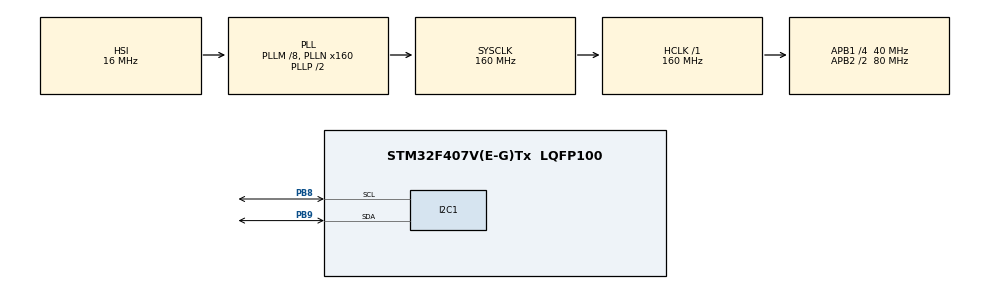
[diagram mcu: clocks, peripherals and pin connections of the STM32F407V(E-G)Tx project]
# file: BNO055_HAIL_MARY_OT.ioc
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Dma.I2C1_RX.1.Direction=DMA_PERIPH_TO_MEMORY
Dma.I2C1_RX.1.FIFOMode=DMA_FIFOMODE_DISABLE
Dma.I2C1_RX.1.Instance=DMA1_Stream0
Dma.I2C1_RX.1.MemDataAlignment=DMA_MDATAALIGN_BYTE
Dma.I2C1_RX.1.MemInc=DMA_MINC_ENABLE
Dma.I2C1_RX.1.Mode=DMA_NORMAL
Dma.I2C1_RX.1.PeriphDataAlignment=DMA_PDATAALIGN_BYTE
Dma.I2C1_RX.1.PeriphInc=DMA_PINC_DISABLE
Dma.I2C1_RX.1.Priority=DMA_PRIORITY_LOW
Dma.I2C1_TX.0.Direction=DMA_MEMORY_TO_PERIPH
Dma.I2C1_TX.0.FIFOMode=DMA_FIFOMODE_DISABLE
Dma.I2C1_TX.0.Instance=DMA1_Stream6
Dma.I2C1_TX.0.MemDataAlignment=DMA_MDATAALIGN_BYTE
Dma.I2C1_TX.0.MemInc=DMA_MINC_ENABLE
Dma.I2C1_TX.0.Mode=DMA_NORMAL
Dma.I2C1_TX.0.PeriphDataAlignment=DMA_PDATAALIGN_BYTE
Dma.I2C1_TX.0.PeriphInc=DMA_PINC_DISABLE
Dma.I2C1_TX.0.Priority=DMA_PRIORITY_LOW
Dma.Request0=I2C1_TX
Dma.Request1=I2C1_RX
Mcu.Family=STM32F4
Mcu.Name=STM32F407V(E-G)Tx
Mcu.Package=LQFP100
NVIC.DMA1_Stream0_IRQn=true\:0\:0\:false\:false\:true\:false\:true\:true
NVIC.DMA1_Stream6_IRQn=true\:0\:0\:false\:false\:true\:false\:true\:true
NVIC.PriorityGroup=NVIC_PRIORITYGROUP_0
PB8.Mode=I2C
PB8.Signal=I2C1_SCL
PB9.Mode=I2C
PB9.Signal=I2C1_SDA
ProjectManager.HeapSize=0x200
ProjectManager.StackSize=0x400
ProjectManager.TargetToolchain=STM32CubeIDE
RCC.48MHZClocksFreq_Value=45714285.71428572
RCC.AHBFreq_Value=160000000
RCC.APB1CLKDivider=RCC_HCLK_DIV4
RCC.APB1Freq_Value=40000000
RCC.APB1TimFreq_Value=80000000
RCC.APB2CLKDivider=RCC_HCLK_DIV2
RCC.APB2Freq_Value=80000000
RCC.APB2TimFreq_Value=160000000
RCC.CortexFreq_Value=160000000
RCC.HCLKFreq_Value=160000000
RCC.HSE_VALUE=8000000
RCC.HSI_VALUE=16000000
RCC.LSE_VALUE=32768
RCC.PLLM=8
RCC.PLLN=160
RCC.PLLQ=7
RCC.SYSCLKFreq_VALUE=160000000
RCC.SYSCLKSource=RCC_SYSCLKSOURCE_PLLCLK
RCC.VCOOutputFreq_Value=320000000
board=STM32F407G-DISC1

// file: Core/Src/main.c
/* USER CODE BEGIN Header */
/**
 ******************************************************************************
 * @file           : main.c
 * @brief          : Main program body
 ******************************************************************************
 * @attention
 *
 * Copyright (c) 2023 STMicroelectronics.
 * All rights reserved.
 *
 * This software is licensed under terms that can be found in the LICENSE file
 * in the root directory of this software component.
 * If no LICENSE file comes with this software, it is provided AS-IS.
 *
 ******************************************************************************
 */
/* USER CODE END Header */
#include "main.h"
#include "dma.h"
#include "i2c.h"
#include "gpio.h"
#include "stdio.h"
#include "accel.h"

void SystemClock_Config(void);

/* USER CODE BEGIN 0 */
extern void initialise_monitor_handles(void);
/* USER CODE END 0 */

int main(void)
{
	/* USER CODE BEGIN 1 */
	initialise_monitor_handles();
	printf("Hello mate\n");

	uint8_t		imu_readings[IMU_NUMBER_OF_BYTES];
	int16_t 	accel_data[3];
	float		acc_x, acc_y, acc_z;

	int16_t 	gyro_data[3];
	float		gyr_x, gyr_y, gyr_z;

	/* USER CODE END 1 */

	/* MCU Configuration--------------------------------------------------------*/

	/* Reset of all peripherals, Initializes the Flash interface and the Systick. */
	HAL_Init();

	/* Configure the system clock */
	SystemClock_Config();

	/* Initialize all configured peripherals */
	MX_GPIO_Init();
	MX_DMA_Init();
	MX_I2C1_Init();
	/* USER CODE BEGIN 2 */
	BNO055_Init_I2C(&hi2c1);
	/* USER CODE END 2 */

	/* Infinite loop */
	while (1)
	{

		/* USER CODE BEGIN 3 */
		HAL_Delay(300);
		GetAccelData(&hi2c1, (uint8_t*)imu_readings);
		accel_data[0] = (((int16_t)((uint8_t *)(imu_readings))[1] << 8) | ((uint8_t *)(imu_readings))[0]);      // Turn the MSB and LSB into a signed 16-bit value
		accel_data[1] = (((int16_t)((uint8_t *)(imu_readings))[3] << 8) | ((uint8_t *)(imu_readings))[2]);
		accel_data[2] = (((int16_t)((uint8_t *)(imu_readings))[5] << 8) | ((uint8_t *)(imu_readings))[4]);
		acc_x = ((float)(accel_data[0]))/100.0f; //m/s2
		acc_y = ((float)(accel_data[1]))/100.0f;
		acc_z = ((float)(accel_data[2]))/100.0f;

		gyro_data[0] = (((int16_t)((uint8_t *)(imu_readings))[31] <<8 ) | ((uint8_t *)(imu_readings))[12]);      // Turn the MSB and LSB into a signed 16-bit value
		gyro_data[1] = (((int16_t)((uint8_t *)(imu_readings))[15] << 8) | ((uint8_t *)(imu_readings))[14]);
		gyro_data[2] = (((int16_t)((uint8_t *)(imu_readings))[17] << 8 ) | ((uint8_t *)(imu_readings))[16]);
		gyr_x = ((float)(accel_data[0]))/100.0f; //m/s2
		gyr_y = ((float)(accel_data[1]))/100.0f;
		gyr_z = ((float)(accel_data[2]))/100.0f;
	}
	/* USER CODE END 3 */
}

void SystemClock_Config(void)
{
	RCC_OscInitTypeDef RCC_OscInitStruct = {0};
	RCC_ClkInitTypeDef RCC_ClkInitStruct = {0};

	/** Configure the main internal regulator output voltage
	 */
	__HAL_RCC_PWR_CLK_ENABLE();
	__HAL_PWR_VOLTAGESCALING_CONFIG(PWR_REGULATOR_VOLTAGE_SCALE1);

	/** Initializes the RCC Oscillators according to the specified parameters
	 * in the RCC_OscInitTypeDef structure.
	 */
	RCC_OscInitStruct.OscillatorType = RCC_OSCILLATORTYPE_HSI;
	RCC_OscInitStruct.HSIState = RCC_HSI_ON;
	RCC_OscInitStruct.HSICalibrationValue = RCC_HSICALIBRATION_DEFAULT;
	RCC_OscInitStruct.PLL.PLLState = RCC_PLL_ON;
	RCC_OscInitStruct.PLL.PLLSource = RCC_PLLSOURCE_HSI;
	RCC_OscInitStruct.PLL.PLLM = 8;
	RCC_OscInitStruct.PLL.PLLN = 160;
	RCC_OscInitStruct.PLL.PLLP = RCC_PLLP_DIV2;
	RCC_OscInitStruct.PLL.PLLQ = 7;
	if (HAL_RCC_OscConfig(&RCC_OscInitStruct) != HAL_OK)
	{
		Error_Handler();
	}

	/** Initializes the CPU, AHB and APB buses clocks
	 */
	RCC_ClkInitStruct.ClockType = RCC_CLOCKTYPE_HCLK|RCC_CLOCKTYPE_SYSCLK
			|RCC_CLOCKTYPE_PCLK1|RCC_CLOCKTYPE_PCLK2;
	RCC_ClkInitStruct.SYSCLKSource = RCC_SYSCLKSOURCE_PLLCLK;
	RCC_ClkInitStruct.AHBCLKDivider = RCC_SYSCLK_DIV1;
	RCC_ClkInitStruct.APB1CLKDivider = RCC_HCLK_DIV4;
	RCC_ClkInitStruct.APB2CLKDivider = RCC_HCLK_DIV2;

	if (HAL_RCC_ClockConfig(&RCC_ClkInitStruct, FLASH_LATENCY_5) != HAL_OK)
	{
		Error_Handler();
	}
}

void Error_Handler(void)
{
	__disable_irq();
	while (1)
	{
	}
}
